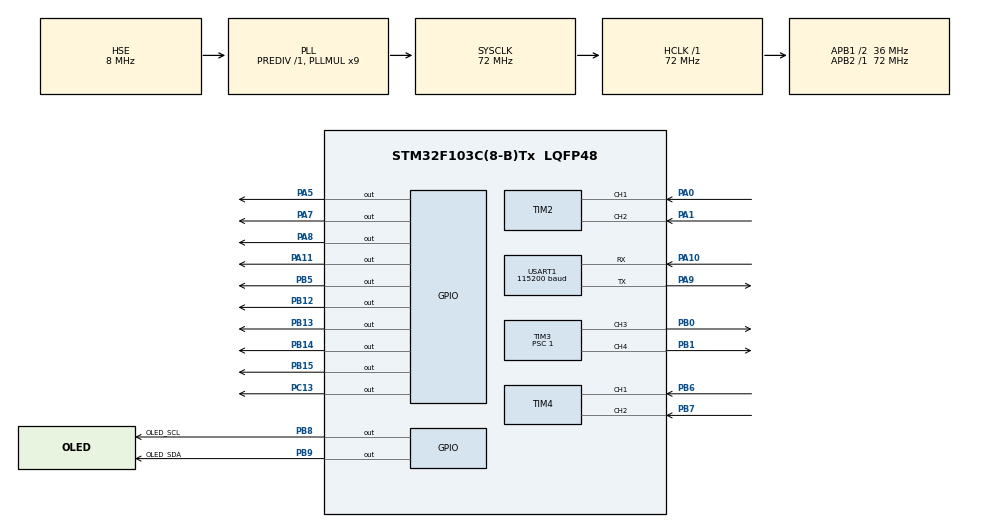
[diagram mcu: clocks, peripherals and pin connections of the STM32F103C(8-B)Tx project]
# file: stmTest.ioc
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Dma.Request0=USART1_RX
Dma.USART1_RX.0.Direction=DMA_PERIPH_TO_MEMORY
Dma.USART1_RX.0.Instance=DMA1_Channel5
Dma.USART1_RX.0.MemDataAlignment=DMA_MDATAALIGN_BYTE
Dma.USART1_RX.0.MemInc=DMA_MINC_ENABLE
Dma.USART1_RX.0.Mode=DMA_NORMAL
Dma.USART1_RX.0.PeriphDataAlignment=DMA_PDATAALIGN_BYTE
Dma.USART1_RX.0.PeriphInc=DMA_PINC_DISABLE
Dma.USART1_RX.0.Priority=DMA_PRIORITY_MEDIUM
Mcu.Family=STM32F1
Mcu.Name=STM32F103C(8-B)Tx
Mcu.Package=LQFP48
NVIC.DMA1_Channel5_IRQn=true\:14\:0\:true\:false\:true\:false\:true\:true
NVIC.PriorityGroup=NVIC_PRIORITYGROUP_4
NVIC.TIM1_UP_IRQn=true\:0\:0\:false\:false\:true\:true\:true\:true
NVIC.USART1_IRQn=true\:14\:0\:true\:false\:true\:true\:true\:true
PA0-WKUP.Signal=S_TIM2_CH1_ETR
PA1.Signal=S_TIM2_CH2
PA10.Mode=Asynchronous
PA10.Signal=USART1_RX
PA11.Signal=GPIO_Output
PA13.Mode=Serial_Wire
PA13.Signal=SYS_JTMS-SWDIO
PA14.Mode=Serial_Wire
PA14.Signal=SYS_JTCK-SWCLK
PA5.Signal=GPIO_Output
PA7.Signal=GPIO_Output
PA8.Signal=GPIO_Output
PA9.Mode=Asynchronous
PA9.Signal=USART1_TX
PB0.Signal=S_TIM3_CH3
PB1.Signal=S_TIM3_CH4
PB12.Signal=GPIO_Output
PB13.Signal=GPIO_Output
PB14.Signal=GPIO_Output
PB15.Signal=GPIO_Output
PB5.GPIO_PuPd=GPIO_NOPULL
PB5.PinState=GPIO_PIN_SET
PB5.Signal=GPIO_Output
PB6.Signal=S_TIM4_CH1
PB7.Signal=S_TIM4_CH2
PB8.GPIO_Label=OLED_SCL
PB8.GPIO_ModeDefaultOutputPP=GPIO_MODE_OUTPUT_PP
PB8.GPIO_PuPd=GPIO_NOPULL
PB8.GPIO_Speed=GPIO_SPEED_FREQ_HIGH
PB8.PinState=GPIO_PIN_SET
PB8.Signal=GPIO_Output
PB9.GPIO_Label=OLED_SDA
PB9.GPIO_ModeDefaultOutputPP=GPIO_MODE_OUTPUT_PP
PB9.GPIO_PuPd=GPIO_NOPULL
PB9.GPIO_Speed=GPIO_SPEED_FREQ_HIGH
PB9.PinState=GPIO_PIN_SET
PB9.Signal=GPIO_Output
PC13-TAMPER-RTC.Signal=GPIO_Output
PD0-OSC_IN.Mode=HSE-External-Oscillator
PD0-OSC_IN.Signal=RCC_OSC_IN
PD1-OSC_OUT.Mode=HSE-External-Oscillator
PD1-OSC_OUT.Signal=RCC_OSC_OUT
ProjectManager.HeapSize=0x200
ProjectManager.StackSize=0x400
ProjectManager.TargetToolchain=MDK-ARM V5.32
RCC.AHBFreq_Value=72000000
RCC.APB1CLKDivider=RCC_HCLK_DIV2
RCC.APB1Freq_Value=36000000
RCC.APB1TimFreq_Value=72000000
RCC.APB2Freq_Value=72000000
RCC.APB2TimFreq_Value=72000000
RCC.HCLKFreq_Value=72000000
RCC.PLLMUL=RCC_PLL_MUL9
RCC.PLLSourceVirtual=RCC_PLLSOURCE_HSE
RCC.SYSCLKFreq_VALUE=72000000
RCC.SYSCLKSource=RCC_SYSCLKSOURCE_PLLCLK
RCC.USBFreq_Value=72000000
SH.S_TIM2_CH1_ETR.0=TIM2_CH1,Encoder_Interface
SH.S_TIM2_CH2.0=TIM2_CH2,Encoder_Interface
SH.S_TIM3_CH3.0=TIM3_CH3,PWM Generation3 CH3
SH.S_TIM3_CH4.0=TIM3_CH4,PWM Generation4 CH4
SH.S_TIM4_CH1.0=TIM4_CH1,Encoder_Interface
SH.S_TIM4_CH2.0=TIM4_CH2,Encoder_Interface
TIM1.AutoReloadPreload=TIM_AUTORELOAD_PRELOAD_ENABLE
TIM1.Period=49
TIM1.Prescaler=7199
TIM2.EncoderMode=TIM_ENCODERMODE_TI1
TIM3.Channel-PWM\ Generation3\ CH3=TIM_CHANNEL_3
TIM3.Channel-PWM\ Generation4\ CH4=TIM_CHANNEL_4
TIM3.Period=3599
TIM3.Prescaler=1
USART1.BaudRate=115200
USART1.VirtualMode=VM_ASYNC
VP_TIM1_VS_ClockSourceINT.Mode=Internal
VP_TIM3_VS_ClockSourceINT.Mode=Internal
board=custom

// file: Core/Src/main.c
/* USER CODE BEGIN Header */
/**
  ******************************************************************************
  * @file           : main.c
  * @brief          : Main program body
  ******************************************************************************
  * @attention
  *
  * Copyright (c) 2025 STMicroelectronics.
  * All rights reserved.
  *
  * This software is licensed under terms that can be found in the LICENSE file
  * in the root directory of this software component.
  * If no LICENSE file comes with this software, it is provided AS-IS.
  *
  ******************************************************************************
  */
/* USER CODE END Header */
#include "main.h"

/* USER CODE BEGIN Includes */
#include "app_init.h"
/* USER CODE END Includes */

/* USER CODE BEGIN PD */
extern uint8_t s_pid_uart_rx_buf[PID_UART1_RX_BUF_SIZE];
/* USER CODE END PD */

TIM_HandleTypeDef htim1;
TIM_HandleTypeDef htim2;
TIM_HandleTypeDef htim3;
TIM_HandleTypeDef htim4;

UART_HandleTypeDef huart1;
DMA_HandleTypeDef hdma_usart1_rx;

void SystemClock_Config(void);
static void MX_GPIO_Init(void);
static void MX_DMA_Init(void);
static void MX_USART1_UART_Init(void);
static void MX_TIM2_Init(void);
static void MX_TIM3_Init(void);
static void MX_TIM4_Init(void);
static void MX_TIM1_Init(void);

int main(void)
{

  /* MCU Configuration--------------------------------------------------------*/

  /* Reset of all peripherals, Initializes the Flash interface and the Systick. */
  HAL_Init();

  /* Configure the system clock */
  SystemClock_Config();

  /* Initialize all configured peripherals */
  MX_GPIO_Init();
  MX_DMA_Init();
  MX_USART1_UART_Init();
  MX_TIM2_Init();
  MX_TIM3_Init();
  MX_TIM4_Init();

  /* USER CODE BEGIN 2 */
  App_Init();
  MX_TIM1_Init();
  /* USER CODE END 2 */

  /* Infinite loop */
  while (1)
  {

    /* USER CODE BEGIN 3 */
    App_MainLoop();
    /* USER CODE END 3 */
  }
  /* USER CODE END 2 */

}

void SystemClock_Config(void)
{
  RCC_OscInitTypeDef RCC_OscInitStruct = {0};
  RCC_ClkInitTypeDef RCC_ClkInitStruct = {0};

  /** Initializes the RCC Oscillators according to the specified parameters
  * in the RCC_OscInitTypeDef structure.
  */
  RCC_OscInitStruct.OscillatorType = RCC_OSCILLATORTYPE_HSE;
  RCC_OscInitStruct.HSEState = RCC_HSE_ON;
  RCC_OscInitStruct.HSEPredivValue = RCC_HSE_PREDIV_DIV1;
  RCC_OscInitStruct.HSIState = RCC_HSI_ON;
  RCC_OscInitStruct.PLL.PLLState = RCC_PLL_ON;
  RCC_OscInitStruct.PLL.PLLSource = RCC_PLLSOURCE_HSE;
  RCC_OscInitStruct.PLL.PLLMUL = RCC_PLL_MUL9;
  if (HAL_RCC_OscConfig(&RCC_OscInitStruct) != HAL_OK)
  {
    Error_Handler();
  }

  /** Initializes the CPU, AHB and APB buses clocks
  */
  RCC_ClkInitStruct.ClockType = RCC_CLOCKTYPE_HCLK|RCC_CLOCKTYPE_SYSCLK
                              |RCC_CLOCKTYPE_PCLK1|RCC_CLOCKTYPE_PCLK2;
  RCC_ClkInitStruct.SYSCLKSource = RCC_SYSCLKSOURCE_PLLCLK;
  RCC_ClkInitStruct.AHBCLKDivider = RCC_SYSCLK_DIV1;
  RCC_ClkInitStruct.APB1CLKDivider = RCC_HCLK_DIV2;
  RCC_ClkInitStruct.APB2CLKDivider = RCC_HCLK_DIV1;

  if (HAL_RCC_ClockConfig(&RCC_ClkInitStruct, FLASH_LATENCY_2) != HAL_OK)
  {
    Error_Handler();
  }
}

static void MX_TIM1_Init(void)
{

  TIM_ClockConfigTypeDef sClockSourceConfig = {0};
  TIM_MasterConfigTypeDef sMasterConfig = {0};

  htim1.Instance = TIM1;
  htim1.Init.Prescaler = 7199;
  htim1.Init.CounterMode = TIM_COUNTERMODE_UP;
  htim1.Init.Period = 49;
  htim1.Init.ClockDivision = TIM_CLOCKDIVISION_DIV1;
  htim1.Init.RepetitionCounter = 0;
  htim1.Init.AutoReloadPreload = TIM_AUTORELOAD_PRELOAD_ENABLE;
  if (HAL_TIM_Base_Init(&htim1) != HAL_OK)
  {
    Error_Handler();
  }
  sClockSourceConfig.ClockSource = TIM_CLOCKSOURCE_INTERNAL;
  if (HAL_TIM_ConfigClockSource(&htim1, &sClockSourceConfig) != HAL_OK)
  {
    Error_Handler();
  }
  sMasterConfig.MasterOutputTrigger = TIM_TRGO_RESET;
  sMasterConfig.MasterSlaveMode = TIM_MASTERSLAVEMODE_DISABLE;
  if (HAL_TIMEx_MasterConfigSynchronization(&htim1, &sMasterConfig) != HAL_OK)
  {
    Error_Handler();
  }
  /* USER CODE BEGIN TIM1_Init 2 */
  __HAL_TIM_CLEAR_FLAG(&htim1, TIM_FLAG_UPDATE);
  if (HAL_TIM_Base_Start_IT(&htim1) != HAL_OK)
  {
    Error_Handler();
  }
  /* USER CODE END TIM1_Init 2 */

}

static void MX_TIM2_Init(void)
{

  TIM_Encoder_InitTypeDef sConfig = {0};
  TIM_MasterConfigTypeDef sMasterConfig = {0};

  htim2.Instance = TIM2;
  htim2.Init.Prescaler = 0;
  htim2.Init.CounterMode = TIM_COUNTERMODE_UP;
  htim2.Init.Period = 65535;
  htim2.Init.ClockDivision = TIM_CLOCKDIVISION_DIV1;
  htim2.Init.AutoReloadPreload = TIM_AUTORELOAD_PRELOAD_DISABLE;
  sConfig.EncoderMode = TIM_ENCODERMODE_TI12;
  sConfig.IC1Polarity = TIM_ICPOLARITY_RISING;
  sConfig.IC1Selection = TIM_ICSELECTION_DIRECTTI;
  sConfig.IC1Prescaler = TIM_ICPSC_DIV1;
  sConfig.IC1Filter = 0;
  sConfig.IC2Polarity = TIM_ICPOLARITY_RISING;
  sConfig.IC2Selection = TIM_ICSELECTION_DIRECTTI;
  sConfig.IC2Prescaler = TIM_ICPSC_DIV1;
  sConfig.IC2Filter = 0;
  if (HAL_TIM_Encoder_Init(&htim2, &sConfig) != HAL_OK)
  {
    Error_Handler();
  }
  sMasterConfig.MasterOutputTrigger = TIM_TRGO_RESET;
  sMasterConfig.MasterSlaveMode = TIM_MASTERSLAVEMODE_DISABLE;
  if (HAL_TIMEx_MasterConfigSynchronization(&htim2, &sMasterConfig) != HAL_OK)
  {
    Error_Handler();
  }

}

static void MX_TIM3_Init(void)
{

  TIM_ClockConfigTypeDef sClockSourceConfig = {0};
  TIM_MasterConfigTypeDef sMasterConfig = {0};
  TIM_OC_InitTypeDef sConfigOC = {0};

  htim3.Instance = TIM3;
  htim3.Init.Prescaler = 1;
  htim3.Init.CounterMode = TIM_COUNTERMODE_UP;
  htim3.Init.Period = 3599;
  htim3.Init.ClockDivision = TIM_CLOCKDIVISION_DIV1;
  htim3.Init.AutoReloadPreload = TIM_AUTORELOAD_PRELOAD_DISABLE;
  if (HAL_TIM_Base_Init(&htim3) != HAL_OK)
  {
    Error_Handler();
  }
  sClockSourceConfig.ClockSource = TIM_CLOCKSOURCE_INTERNAL;
  if (HAL_TIM_ConfigClockSource(&htim3, &sClockSourceConfig) != HAL_OK)
  {
    Error_Handler();
  }
  if (HAL_TIM_PWM_Init(&htim3) != HAL_OK)
  {
    Error_Handler();
  }
  sMasterConfig.MasterOutputTrigger = TIM_TRGO_RESET;
  sMasterConfig.MasterSlaveMode = TIM_MASTERSLAVEMODE_DISABLE;
  if (HAL_TIMEx_MasterConfigSynchronization(&htim3, &sMasterConfig) != HAL_OK)
  {
    Error_Handler();
  }
  sConfigOC.OCMode = TIM_OCMODE_PWM1;
  sConfigOC.Pulse = 0;
  sConfigOC.OCPolarity = TIM_OCPOLARITY_HIGH;
  sConfigOC.OCFastMode = TIM_OCFAST_DISABLE;
  if (HAL_TIM_PWM_ConfigChannel(&htim3, &sConfigOC, TIM_CHANNEL_3) != HAL_OK)
  {
    Error_Handler();
  }
  if (HAL_TIM_PWM_ConfigChannel(&htim3, &sConfigOC, TIM_CHANNEL_4) != HAL_OK)
  {
    Error_Handler();
  }
  /* USER CODE BEGIN TIM3_Init 2 */
  HAL_TIM_PWM_Start(&htim3, TIM_CHANNEL_3);
  HAL_TIM_PWM_Start(&htim3, TIM_CHANNEL_4);
  /* USER CODE END TIM3_Init 2 */
  HAL_TIM_MspPostInit(&htim3);

}

static void MX_TIM4_Init(void)
{

  TIM_Encoder_InitTypeDef sConfig = {0};
  TIM_MasterConfigTypeDef sMasterConfig = {0};

  htim4.Instance = TIM4;
  htim4.Init.Prescaler = 0;
  htim4.Init.CounterMode = TIM_COUNTERMODE_UP;
  htim4.Init.Period = 65535;
  htim4.Init.ClockDivision = TIM_CLOCKDIVISION_DIV1;
  htim4.Init.AutoReloadPreload = TIM_AUTORELOAD_PRELOAD_DISABLE;
  sConfig.EncoderMode = TIM_ENCODERMODE_TI12;
  sConfig.IC1Polarity = TIM_ICPOLARITY_RISING;
  sConfig.IC1Selection = TIM_ICSELECTION_DIRECTTI;
  sConfig.IC1Prescaler = TIM_ICPSC_DIV1;
  sConfig.IC1Filter = 0;
  sConfig.IC2Polarity = TIM_ICPOLARITY_RISING;
  sConfig.IC2Selection = TIM_ICSELECTION_DIRECTTI;
  sConfig.IC2Prescaler = TIM_ICPSC_DIV1;
  sConfig.IC2Filter = 0;
  if (HAL_TIM_Encoder_Init(&htim4, &sConfig) != HAL_OK)
  {
    Error_Handler();
  }
  sMasterConfig.MasterOutputTrigger = TIM_TRGO_RESET;
  sMasterConfig.MasterSlaveMode = TIM_MASTERSLAVEMODE_DISABLE;
  if (HAL_TIMEx_MasterConfigSynchronization(&htim4, &sMasterConfig) != HAL_OK)
  {
    Error_Handler();
  }

}

static void MX_USART1_UART_Init(void)
{

  huart1.Instance = USART1;
  huart1.Init.BaudRate = 115200;
  huart1.Init.WordLength = UART_WORDLENGTH_8B;
  huart1.Init.StopBits = UART_STOPBITS_1;
  huart1.Init.Parity = UART_PARITY_NONE;
  huart1.Init.Mode = UART_MODE_TX_RX;
  huart1.Init.HwFlowCtl = UART_HWCONTROL_NONE;
  huart1.Init.OverSampling = UART_OVERSAMPLING_16;
  if (HAL_UART_Init(&huart1) != HAL_OK)
  {
    Error_Handler();
  }
  /* USER CODE BEGIN USART1_Init 2 */

  // HAL_UART_Receive_DMA(&huart1, s_pid_uart_rx_buf, PID_UART1_RX_BUF_SIZE);
  //__HAL_UART_ENABLE_IT(&huart1, UART_IT_RXNE);
  /* USER CODE END USART1_Init 2 */

}

static void MX_DMA_Init(void)
{

  /* DMA controller clock enable */
  __HAL_RCC_DMA1_CLK_ENABLE();

  /* DMA interrupt init */
  /* DMA1_Channel5_IRQn interrupt configuration */
  HAL_NVIC_SetPriority(DMA1_Channel5_IRQn, 14, 0);
  HAL_NVIC_EnableIRQ(DMA1_Channel5_IRQn);

}

static void MX_GPIO_Init(void)
{
  GPIO_InitTypeDef GPIO_InitStruct = {0};

  /* GPIO Ports Clock Enable */
  __HAL_RCC_GPIOC_CLK_ENABLE();
  __HAL_RCC_GPIOD_CLK_ENABLE();
  __HAL_RCC_GPIOA_CLK_ENABLE();
  __HAL_RCC_GPIOB_CLK_ENABLE();

  /*Configure GPIO pin Output Level */
  HAL_GPIO_WritePin(GPIOC, GPIO_PIN_13, GPIO_PIN_RESET);

  /*Configure GPIO pin Output Level */
  HAL_GPIO_WritePin(GPIOA, GPIO_PIN_5|GPIO_PIN_7|GPIO_PIN_8|GPIO_PIN_11, GPIO_PIN_RESET);

  /*Configure GPIO pin Output Level */
  HAL_GPIO_WritePin(GPIOB, GPIO_PIN_12|GPIO_PIN_13|GPIO_PIN_14|GPIO_PIN_15, GPIO_PIN_RESET);

  /*Configure GPIO pin Output Level */
  HAL_GPIO_WritePin(GPIOB, GPIO_PIN_5|OLED_SCL_Pin|OLED_SDA_Pin, GPIO_PIN_SET);

  /*Configure GPIO pin : PC13 */
  GPIO_InitStruct.Pin = GPIO_PIN_13;
  GPIO_InitStruct.Mode = GPIO_MODE_OUTPUT_PP;
  GPIO_InitStruct.Pull = GPIO_NOPULL;
  GPIO_InitStruct.Speed = GPIO_SPEED_FREQ_LOW;
  HAL_GPIO_Init(GPIOC, &GPIO_InitStruct);

  /*Configure GPIO pins : PA5 PA7 PA8 PA11 */
  GPIO_InitStruct.Pin = GPIO_PIN_5|GPIO_PIN_7|GPIO_PIN_8|GPIO_PIN_11;
  GPIO_InitStruct.Mode = GPIO_MODE_OUTPUT_PP;
  GPIO_InitStruct.Pull = GPIO_NOPULL;
  GPIO_InitStruct.Speed = GPIO_SPEED_FREQ_LOW;
  HAL_GPIO_Init(GPIOA, &GPIO_InitStruct);

  /*Configure GPIO pins : PB12 PB13 PB14 PB15
                           PB5 */
  GPIO_InitStruct.Pin = GPIO_PIN_12|GPIO_PIN_13|GPIO_PIN_14|GPIO_PIN_15
                          |GPIO_PIN_5;
  GPIO_InitStruct.Mode = GPIO_MODE_OUTPUT_PP;
  GPIO_InitStruct.Pull = GPIO_NOPULL;
  GPIO_InitStruct.Speed = GPIO_SPEED_FREQ_LOW;
  HAL_GPIO_Init(GPIOB, &GPIO_InitStruct);

  /*Configure GPIO pins : OLED_SCL_Pin OLED_SDA_Pin */
  GPIO_InitStruct.Pin = OLED_SCL_Pin|OLED_SDA_Pin;
  GPIO_InitStruct.Mode = GPIO_MODE_OUTPUT_PP;
  GPIO_InitStruct.Pull = GPIO_NOPULL;
  GPIO_InitStruct.Speed = GPIO_SPEED_FREQ_HIGH;
  HAL_GPIO_Init(GPIOB, &GPIO_InitStruct);

}

void Error_Handler(void)
{
  __disable_irq();
  while (1)
  {
  }
}
